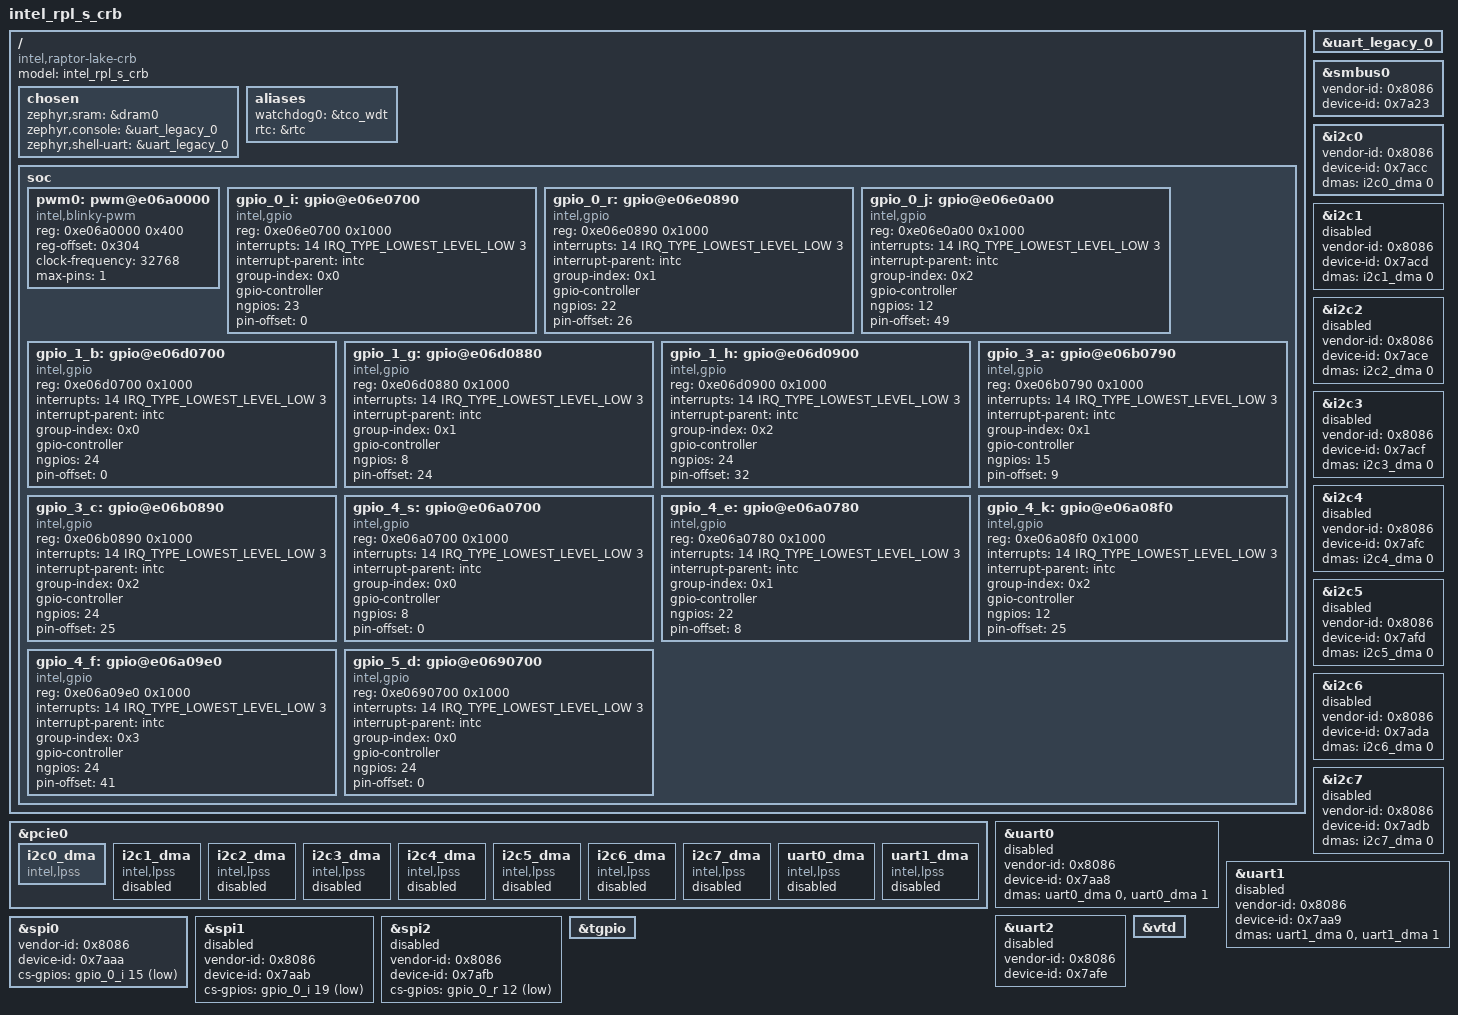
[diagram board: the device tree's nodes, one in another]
/*
 * Copyright (c) 2022 Intel Corporation
 * SPDX-License-Identifier: Apache-2.0
 */

/dts-v1/;

#include <mem.h>

#define DT_DRAM_SIZE		DT_SIZE_M(2048)

#include <intel/x86_64.dtsi>

/ {
	model = "intel_rpl_s_crb";
	compatible = "intel,raptor-lake-crb";

	chosen {
		zephyr,sram = &dram0;
		zephyr,console = &uart_legacy_0;
		zephyr,shell-uart = &uart_legacy_0;
	};

	aliases {
		watchdog0 = &tco_wdt;
		rtc = &rtc;
	};

	soc {
		pwm0: pwm@e06a0000 {
			compatible = "intel,blinky-pwm";
			reg = <0xe06a0000 0x400>;
			reg-offset = <0x304>;
			clock-frequency = <32768>;
			max-pins = <1>;
			#pwm-cells = <2>;
			status = "okay";
		};

		gpio_0_i: gpio@e06e0700 {
			compatible = "intel,gpio";
			reg = <0xe06e0700 0x1000>;
			interrupts = <14 IRQ_TYPE_LOWEST_LEVEL_LOW 3>;
			interrupt-parent = <&intc>;
			group-index = <0x0>;
			gpio-controller;
			#gpio-cells = <2>;
			ngpios = <23>;
			pin-offset = <0>;

			status = "okay";
		};

		gpio_0_r: gpio@e06e0890 {
			compatible = "intel,gpio";
			reg = <0xe06e0890 0x1000>;
			interrupts = <14 IRQ_TYPE_LOWEST_LEVEL_LOW 3>;
			interrupt-parent = <&intc>;
			group-index = <0x1>;
			gpio-controller;
			#gpio-cells = <2>;
			ngpios = <22>;
			pin-offset = <26>;

			status = "okay";
		};

		gpio_0_j: gpio@e06e0a00 {
			compatible = "intel,gpio";
			reg = <0xe06e0a00 0x1000>;
			interrupts = <14 IRQ_TYPE_LOWEST_LEVEL_LOW 3>;
			interrupt-parent = <&intc>;
			group-index = <0x2>;
			gpio-controller;
			#gpio-cells = <2>;
			ngpios = <12>;
			pin-offset = <49>;

			status = "okay";
		};

		gpio_1_b: gpio@e06d0700 {
			compatible = "intel,gpio";
			reg = <0xe06d0700 0x1000>;
			interrupts = <14 IRQ_TYPE_LOWEST_LEVEL_LOW 3>;
			interrupt-parent = <&intc>;
			group-index = <0x0>;
			gpio-controller;
			#gpio-cells = <2>;
			ngpios = <24>;
			pin-offset = <0>;

			status = "okay";
		};

		gpio_1_g: gpio@e06d0880 {
			compatible = "intel,gpio";
			reg = <0xe06d0880 0x1000>;
			interrupts = <14 IRQ_TYPE_LOWEST_LEVEL_LOW 3>;
			interrupt-parent = <&intc>;
			group-index = <0x1>;
			gpio-controller;
			#gpio-cells = <2>;
			ngpios = <8>;
			pin-offset = <24>;

			status = "okay";
		};

		gpio_1_h: gpio@e06d0900 {
			compatible = "intel,gpio";
			reg = <0xe06d0900 0x1000>;
			interrupts = <14 IRQ_TYPE_LOWEST_LEVEL_LOW 3>;
			interrupt-parent = <&intc>;
			group-index = <0x2>;
			gpio-controller;
			#gpio-cells = <2>;
			ngpios = <24>;
			pin-offset = <32>;

			status = "okay";
		};

		gpio_3_a: gpio@e06b0790 {
			compatible = "intel,gpio";
			reg = <0xe06b0790 0x1000>;
			interrupts = <14 IRQ_TYPE_LOWEST_LEVEL_LOW 3>;
			interrupt-parent = <&intc>;
			group-index = <0x1>;
			gpio-controller;
			#gpio-cells = <2>;
			ngpios = <15>;
			pin-offset = <9>;

			status = "okay";
		};

		gpio_3_c: gpio@e06b0890 {
			compatible = "intel,gpio";
			reg = <0xe06b0890 0x1000>;
			interrupts = <14 IRQ_TYPE_LOWEST_LEVEL_LOW 3>;
			interrupt-parent = <&intc>;
			group-index = <0x2>;
			gpio-controller;
			#gpio-cells = <2>;
			ngpios = <24>;
			pin-offset = <25>;

			status = "okay";
		};

		gpio_4_s: gpio@e06a0700 {
			compatible = "intel,gpio";
			reg = <0xe06a0700 0x1000>;
			interrupts = <14 IRQ_TYPE_LOWEST_LEVEL_LOW 3>;
			interrupt-parent = <&intc>;
			group-index = <0x0>;
			gpio-controller;
			#gpio-cells = <2>;
			ngpios = <8>;
			pin-offset = <0>;

			status = "okay";
		};

		gpio_4_e: gpio@e06a0780 {
			compatible = "intel,gpio";
			reg = <0xe06a0780 0x1000>;
			interrupts = <14 IRQ_TYPE_LOWEST_LEVEL_LOW 3>;
			interrupt-parent = <&intc>;
			group-index = <0x1>;
			gpio-controller;
			#gpio-cells = <2>;
			ngpios = <22>;
			pin-offset = <8>;

			status = "okay";
		};

		gpio_4_k: gpio@e06a08f0 {
			compatible = "intel,gpio";
			reg = <0xe06a08f0 0x1000>;
			interrupts = <14 IRQ_TYPE_LOWEST_LEVEL_LOW 3>;
			interrupt-parent = <&intc>;
			group-index = <0x2>;
			gpio-controller;
			#gpio-cells = <2>;
			ngpios = <12>;
			pin-offset = <25>;

			status = "okay";
		};

		gpio_4_f: gpio@e06a09e0 {
			compatible = "intel,gpio";
			reg = <0xe06a09e0 0x1000>;
			interrupts = <14 IRQ_TYPE_LOWEST_LEVEL_LOW 3>;
			interrupt-parent = <&intc>;
			group-index = <0x3>;
			gpio-controller;
			#gpio-cells = <2>;
			ngpios = <24>;
			pin-offset = <41>;

			status = "okay";
		};

		gpio_5_d: gpio@e0690700 {
			compatible = "intel,gpio";
			reg = <0xe0690700 0x1000>;
			interrupts = <14 IRQ_TYPE_LOWEST_LEVEL_LOW 3>;
			interrupt-parent = <&intc>;
			group-index = <0x0>;
			gpio-controller;
			#gpio-cells = <2>;
			ngpios = <24>;
			pin-offset = <0>;

			status = "okay";
		};
	};
};

&uart_legacy_0 {
	status = "okay";
};

&smbus0 {
	vendor-id = <0x8086>;
	device-id = <0x7a23>;

	status = "okay";
};

&pcie0 {
	i2c0_dma: i2c0_dma {
		compatible = "intel,lpss";
		#dma-cells = <1>;
		status = "okay";
	};

	i2c1_dma: i2c1_dma {
		compatible = "intel,lpss";
		#dma-cells = <1>;
		status = "disabled";
	};

	i2c2_dma: i2c2_dma {
		compatible = "intel,lpss";
		#dma-cells = <1>;
		status = "disabled";
	};

	i2c3_dma: i2c3_dma {
		compatible = "intel,lpss";
		#dma-cells = <1>;
		status = "disabled";
	};

	i2c4_dma: i2c4_dma {
		compatible = "intel,lpss";
		#dma-cells = <1>;
		status = "disabled";
	};

	i2c5_dma: i2c5_dma {
		compatible = "intel,lpss";
		#dma-cells = <1>;
		status = "disabled";
	};

	i2c6_dma: i2c6_dma {
		compatible = "intel,lpss";
		#dma-cells = <1>;
		status = "disabled";
	};

	i2c7_dma: i2c7_dma {
		compatible = "intel,lpss";
		#dma-cells = <1>;
		status = "disabled";
	};

	uart0_dma: uart0_dma {
		compatible = "intel,lpss";
		#dma-cells = <1>;
		status = "disabled";
	};

	uart1_dma: uart1_dma {
		compatible = "intel,lpss";
		#dma-cells = <1>;
		status = "disabled";
	};
};

&i2c0 {
	vendor-id = <0x8086>;
	device-id = <0x7acc>;

	dmas = <&i2c0_dma 0>;

	status = "okay";
};

&i2c1 {
	vendor-id = <0x8086>;
	device-id = <0x7acd>;

	dmas = <&i2c1_dma 0>;

	status = "disabled";
};

&i2c2 {
	vendor-id = <0x8086>;
	device-id = <0x7ace>;

	dmas = <&i2c2_dma 0>;

	status = "disabled";
};

&i2c3 {
	vendor-id = <0x8086>;
	device-id = <0x7acf>;

	dmas = <&i2c3_dma 0>;

	status = "disabled";
};

&i2c4 {
	vendor-id = <0x8086>;
	device-id = <0x7afc>;

	dmas = <&i2c4_dma 0>;

	status = "disabled";
};

&i2c5 {
	vendor-id = <0x8086>;
	device-id = <0x7afd>;

	dmas = <&i2c5_dma 0>;

	status = "disabled";
};

&i2c6 {
	vendor-id = <0x8086>;
	device-id = <0x7ada>;

	dmas = <&i2c6_dma 0>;

	status = "disabled";
};

&i2c7 {
	vendor-id = <0x8086>;
	device-id = <0x7adb>;

	dmas = <&i2c7_dma 0>;

	status = "disabled";
};

&uart0 {
	vendor-id = <0x8086>;
	device-id = <0x7aa8>;

	dmas = <&uart0_dma 0>, <&uart0_dma 1>;
	dma-names = "tx", "rx";

	status = "disabled";
};

&uart1 {
	vendor-id = <0x8086>;
	device-id = <0x7aa9>;

	dmas = <&uart1_dma 0>, <&uart1_dma 1>;
	dma-names = "tx", "rx";

	status = "disabled";
};

&uart2 {
	vendor-id = <0x8086>;
	device-id = <0x7afe>;

	status = "disabled";
};

&spi0 {
	vendor-id = <0x8086>;
	device-id = <0x7aaa>;

	cs-gpios = <&gpio_0_i 15 GPIO_ACTIVE_LOW>;

	status = "okay";
};

&spi1 {
	vendor-id = <0x8086>;
	device-id = <0x7aab>;

	cs-gpios = <&gpio_0_i 19 GPIO_ACTIVE_LOW>;

	status = "disabled";
};

&spi2 {
	vendor-id = <0x8086>;
	device-id = <0x7afb>;

	cs-gpios = <&gpio_0_r 12 GPIO_ACTIVE_LOW>;

	status = "disabled";
};

&vtd {
	status = "okay";
};

&tgpio {
	status = "okay";
};
